# CH579SFR register map
Vendor: WCH Ltd.; Series: CH57x; File version: 1.0
CPU: CM0 r0p0, little endian, no MPU, no FPU, 2 interrupt priority bits
Registers are 8-bit, read-write, reset 0x0 unless marked. A register's access mark holds for its fields unless they carry their own. Offsets are from the block's base; [hi:lo] are bit positions; {n}, {i} and the like mark numbered series.

## PWMx
Base 0x40005000
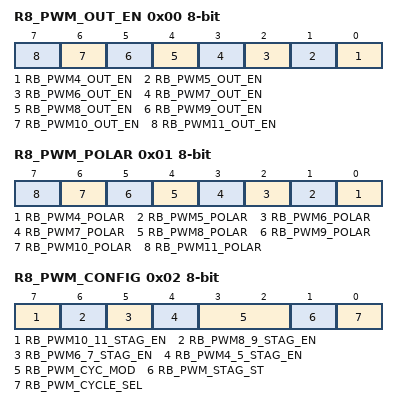
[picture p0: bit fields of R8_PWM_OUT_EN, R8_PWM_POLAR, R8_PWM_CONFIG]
0x00 R8_PWM_OUT_EN — RW, PWM output enable control
  [n-4] RB_PWM{n}_OUT_EN (n=4..11) — RW, PWM{n} output enable
0x01 R8_PWM_POLAR — RW, PWM output polarity control
  [n-4] RB_PWM{n}_POLAR (n=4..11) — RW, PWM{n} output polarity: 0=default low and high action, 1=default high and low action
0x02 R8_PWM_CONFIG — RW, PWM configuration
  [7] RB_PWM10_11_STAG_EN — RW, PWM10/11 stagger output enable: 0=independent output, 1=stagger output
  [6] RB_PWM8_9_STAG_EN — RW, PWM8/9 stagger output enable: 0=independent output, 1=stagger output
  [5] RB_PWM6_7_STAG_EN — RW, PWM6/7 stagger output enable: 0=independent output, 1=stagger output
  [4] RB_PWM4_5_STAG_EN — RW, PWM4/5 stagger output enable: 0=independent output, 1=stagger output
  [3:2] RB_PWM_CYC_MOD — RW, PWM data width mode: 00=8 bits data, 01=7 bits data, 10=6 bits data, 11=5 bits data
  [1] RB_PWM_STAG_ST ro — RO, PWM stagger cycle status
  [0] RB_PWM_CYCLE_SEL — RW, PWM cycle selection: 0=256/128/64/32 clocks, 1=255/127/63/31 clocks
0x03 R8_PWM_CLOCK_DIV — RW, PWM clock divisor
{0x0+i} R8_PWM{i}_DATA (i=4..11) — RW, PWM{i} data holding

## LCD
Base 0x40006000
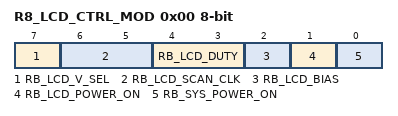
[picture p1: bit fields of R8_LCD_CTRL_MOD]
0x00 R8_LCD_CTRL_MOD
  [7] RB_LCD_V_SEL — RW, LCD drive voltage:0=VIO33*100%(3.3V),1=VIO33*76%(2.5V)
  [6:5] RB_LCD_SCAN_CLK — RW, LCD scan clock select: 00=256Hz, 01=512Hz, 10=1KHz, 11=128Hz
  [4:3] RB_LCD_DUTY — RW, LCD duty select: 00=1/2 duty, 01=1/3 duty, 10=1/4 duty
  [2] RB_LCD_BIAS — RW, LCD bias select: 0=1/2 bias, 1=1/3 bias
  [1] RB_LCD_POWER_ON — RW, LCD analog system enable
  [0] RB_SYS_POWER_ON — RW, LCD digital system enable
0x04 R32_LCD_RAM0 32-bit — RW, LCD driver data0, address 0-3
0x08 R32_LCD_RAM1 32-bit — RW, LCD driver data1, address 4-7
0x0C R32_LCD_RAM2 32-bit — RW, LCD driver data2, address 8-12

## LED
Base 0x40006400
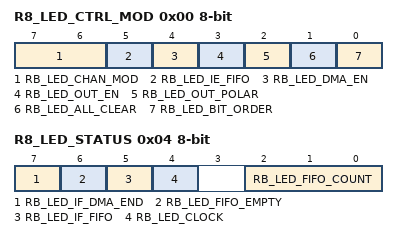
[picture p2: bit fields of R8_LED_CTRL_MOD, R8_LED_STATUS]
0x00 R8_LED_CTRL_MOD — RW, LED mode control
  [7:6] RB_LED_CHAN_MOD — RW, LED channel mode: 00=LED0, 01=LED0/1, 10=LED0~3, 11=LED0~3 and LED2/3 from auxiliary buffer
  [5] RB_LED_IE_FIFO — RW, enable interrupt for LED FIFO less than 2
  [4] RB_LED_DMA_EN — RW, LED DMA enable and DMA interrupt enable
  [3] RB_LED_OUT_EN — RW, LED output enable
  [2] RB_LED_OUT_POLAR — RW, LED output polarity: 0=pass, 1=invert
  [1] RB_LED_ALL_CLEAR — RW, force clear LED FIFO and count
  [0] RB_LED_BIT_ORDER — RW, LED bit data order: 0=LSB first, 1=MSB first
0x01 R8_LED_CLOCK_DIV — RW, LED serial clock divisor
0x04 R8_LED_STATUS access per field — RO, LED status
  [7] RB_LED_IF_DMA_END rw — RW1, interrupt flag for LED DMA completion, cleared by RW1 or write R32/R16_LED_DMA_CNT
  [6] RB_LED_FIFO_EMPTY ro — RO: indicate FIFO empty status
  [5] RB_LED_IF_FIFO rw — RW1, interrupt flag for LED FIFO less than 2, cleared by RW1 or write R32/R16_LED_FIFO
  [4] RB_LED_CLOCK ro — RO, current LED clock level
  [2:0] RB_LED_FIFO_COUNT ro — RO, LED FIFO byte count status, must divided by 2 for width half-word
0x08 R16_LED_FIFO 16-bit wo — WO, LED FIFO register, width is half-word
0x10 R16_LED_DMA_CNT 16-bit — RW, LED DMA main buffer remainder half-word count, exclude auxiliary buffer, automatic decreasing after DMA, only low 12 bit
0x14 R16_LED_DMA_MAIN 16-bit — RW, LED main buffer DMA begin and current address, automatic increasing after DMA
0x18 R16_LED_DMA_AUX 16-bit — RW, LED auxiliary buffer DMA begin and current address, automatic increasing after DMA

## ETH
Base 0x40009000
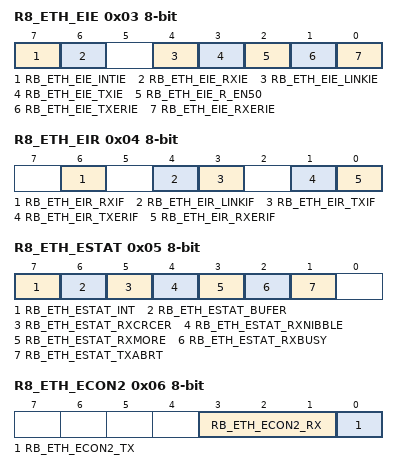
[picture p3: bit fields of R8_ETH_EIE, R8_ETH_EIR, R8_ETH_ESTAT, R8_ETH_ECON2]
0x03 R8_ETH_EIE — soso
  [7] RB_ETH_EIE_INTIE — soso
  [6] RB_ETH_EIE_RXIE — soso
  [4] RB_ETH_EIE_LINKIE — soso
  [3] RB_ETH_EIE_TXIE — soso
  [2] RB_ETH_EIE_R_EN50 — soso
  [1] RB_ETH_EIE_TXERIE — soso
  [0] RB_ETH_EIE_RXERIE — soso
0x04 R8_ETH_EIR — soso
  [6] RB_ETH_EIR_RXIF — soso
  [4] RB_ETH_EIR_LINKIF — soso
  [3] RB_ETH_EIR_TXIF — soso
  [1] RB_ETH_EIR_TXERIF — soso
  [0] RB_ETH_EIR_RXERIF — soso
0x05 R8_ETH_ESTAT ro — soso
  [7] RB_ETH_ESTAT_INT — soso
  [6] RB_ETH_ESTAT_BUFER — soso
  [5] RB_ETH_ESTAT_RXCRCER — soso
  [4] RB_ETH_ESTAT_RXNIBBLE — soso
  [3] RB_ETH_ESTAT_RXMORE — soso
  [2] RB_ETH_ESTAT_RXBUSY — soso
  [1] RB_ETH_ESTAT_TXABRT — soso
0x06 R8_ETH_ECON2 — soso
  [3:1] RB_ETH_ECON2_RX — soso
  [0] RB_ETH_ECON2_TX — soso
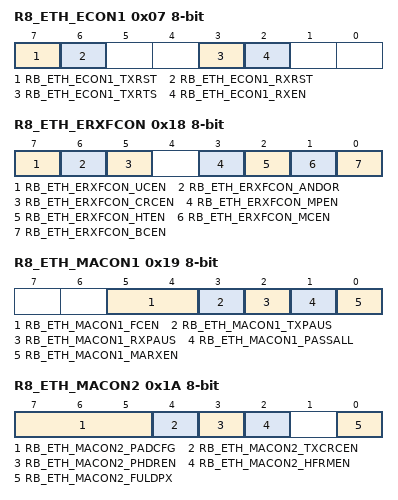
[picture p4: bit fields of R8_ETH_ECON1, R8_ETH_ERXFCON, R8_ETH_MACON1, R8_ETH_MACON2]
0x07 R8_ETH_ECON1 — soso
  [7] RB_ETH_ECON1_TXRST — soso
  [6] RB_ETH_ECON1_RXRST — soso
  [3] RB_ETH_ECON1_TXRTS — soso
  [2] RB_ETH_ECON1_RXEN — soso
0x08 R16_ETH_ETXST 16-bit — soso
0x0A R16_ETH_ETXLN 16-bit — soso
0x0C R16_ETH_ERXST 16-bit — soso
0x0E R16_ETH_ERXLN 16-bit — soso
{0x10+i} R8_ETH_EHT{i} (i=0..7) — soso
0x18 R8_ETH_ERXFCON — soso
  [7] RB_ETH_ERXFCON_UCEN — soso
  [6] RB_ETH_ERXFCON_ANDOR — soso
  [5] RB_ETH_ERXFCON_CRCEN — soso
  [3] RB_ETH_ERXFCON_MPEN — soso
  [2] RB_ETH_ERXFCON_HTEN — soso
  [1] RB_ETH_ERXFCON_MCEN — soso
  [0] RB_ETH_ERXFCON_BCEN — soso
0x19 R8_ETH_MACON1 — soso
  [5:4] RB_ETH_MACON1_FCEN — soso
  [3] RB_ETH_MACON1_TXPAUS — soso
  [2] RB_ETH_MACON1_RXPAUS — soso
  [1] RB_ETH_MACON1_PASSALL — soso
  [0] RB_ETH_MACON1_MARXEN — soso
0x1A R8_ETH_MACON2 — soso
  [7:5] RB_ETH_MACON2_PADCFG — soso
  [4] RB_ETH_MACON2_TXCRCEN — soso
  [3] RB_ETH_MACON2_PHDREN — soso
  [2] RB_ETH_MACON2_HFRMEN — soso
  [0] RB_ETH_MACON2_FULDPX — soso
0x1B R8_ETH_MABBIPG — soso
  [6:0] RB_ETH_MABBIPG_MABBIPG
0x1C R16_ETH_EPAUS 16-bit — soso
0x1E R16_ETH_MAMXFL 16-bit — soso
0x20 R16_ETH_MIRD 16-bit — soso
0x24 R8_ETH_MIREGADR — soso
  [4:0] RB_ETH_MIREGADR_MASK
0x25 R8_ETH_MISTAT ro — soso
0x26 R16_ETH_MIWR 16-bit wo — soso
0x28 R32_ETH_MAADRL 32-bit — soso
0x2C R16_ETH_MAADRH 16-bit — soso
